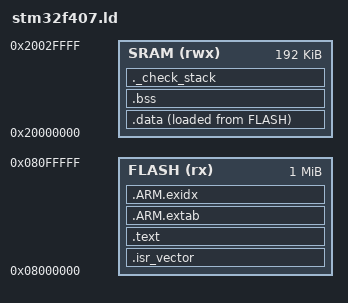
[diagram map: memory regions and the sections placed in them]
/*
 * Linker script for STM32F407VG (1MB flash, 192KB SRAM).
 * Used for Renode simulation and real hardware.
 */

MEMORY
{
    FLASH (rx)  : ORIGIN = 0x08000000, LENGTH = 1024K
    SRAM  (rwx) : ORIGIN = 0x20000000, LENGTH = 192K
}

/* Top of stack — end of SRAM */
_estack = ORIGIN(SRAM) + LENGTH(SRAM);

ENTRY(Reset_Handler)

SECTIONS
{
    /* Interrupt vector table — must be at start of flash */
    .isr_vector :
    {
        . = ALIGN(4);
        KEEP(*(.isr_vector))
        . = ALIGN(4);
    } > FLASH

    /* Code and read-only data */
    .text :
    {
        . = ALIGN(4);
        *(.text)
        *(.text.*)
        *(.rodata)
        *(.rodata.*)
        . = ALIGN(4);
        _etext = .;
    } > FLASH

    /* ARM exception unwind tables */
    .ARM.extab :
    {
        *(.ARM.extab*)
    } > FLASH

    .ARM.exidx :
    {
        __exidx_start = .;
        *(.ARM.exidx*)
        __exidx_end = .;
    } > FLASH

    /* Initialized data — stored in flash, copied to SRAM on boot */
    _sidata = LOADADDR(.data);

    .data :
    {
        . = ALIGN(4);
        _sdata = .;
        *(.data)
        *(.data.*)
        . = ALIGN(4);
        _edata = .;
    } > SRAM AT > FLASH

    /* Uninitialized data — zeroed on boot */
    .bss :
    {
        . = ALIGN(4);
        _sbss = .;
        *(.bss)
        *(.bss.*)
        *(COMMON)
        . = ALIGN(4);
        _ebss = .;
    } > SRAM

    /* Heap end marker (for newlib _sbrk) */
    end = .;
    _end = .;

    /* Stack check — ensure 2KB minimum */
    ._check_stack :
    {
        . = ALIGN(4);
        . = . + 2K;
    } > SRAM
}
